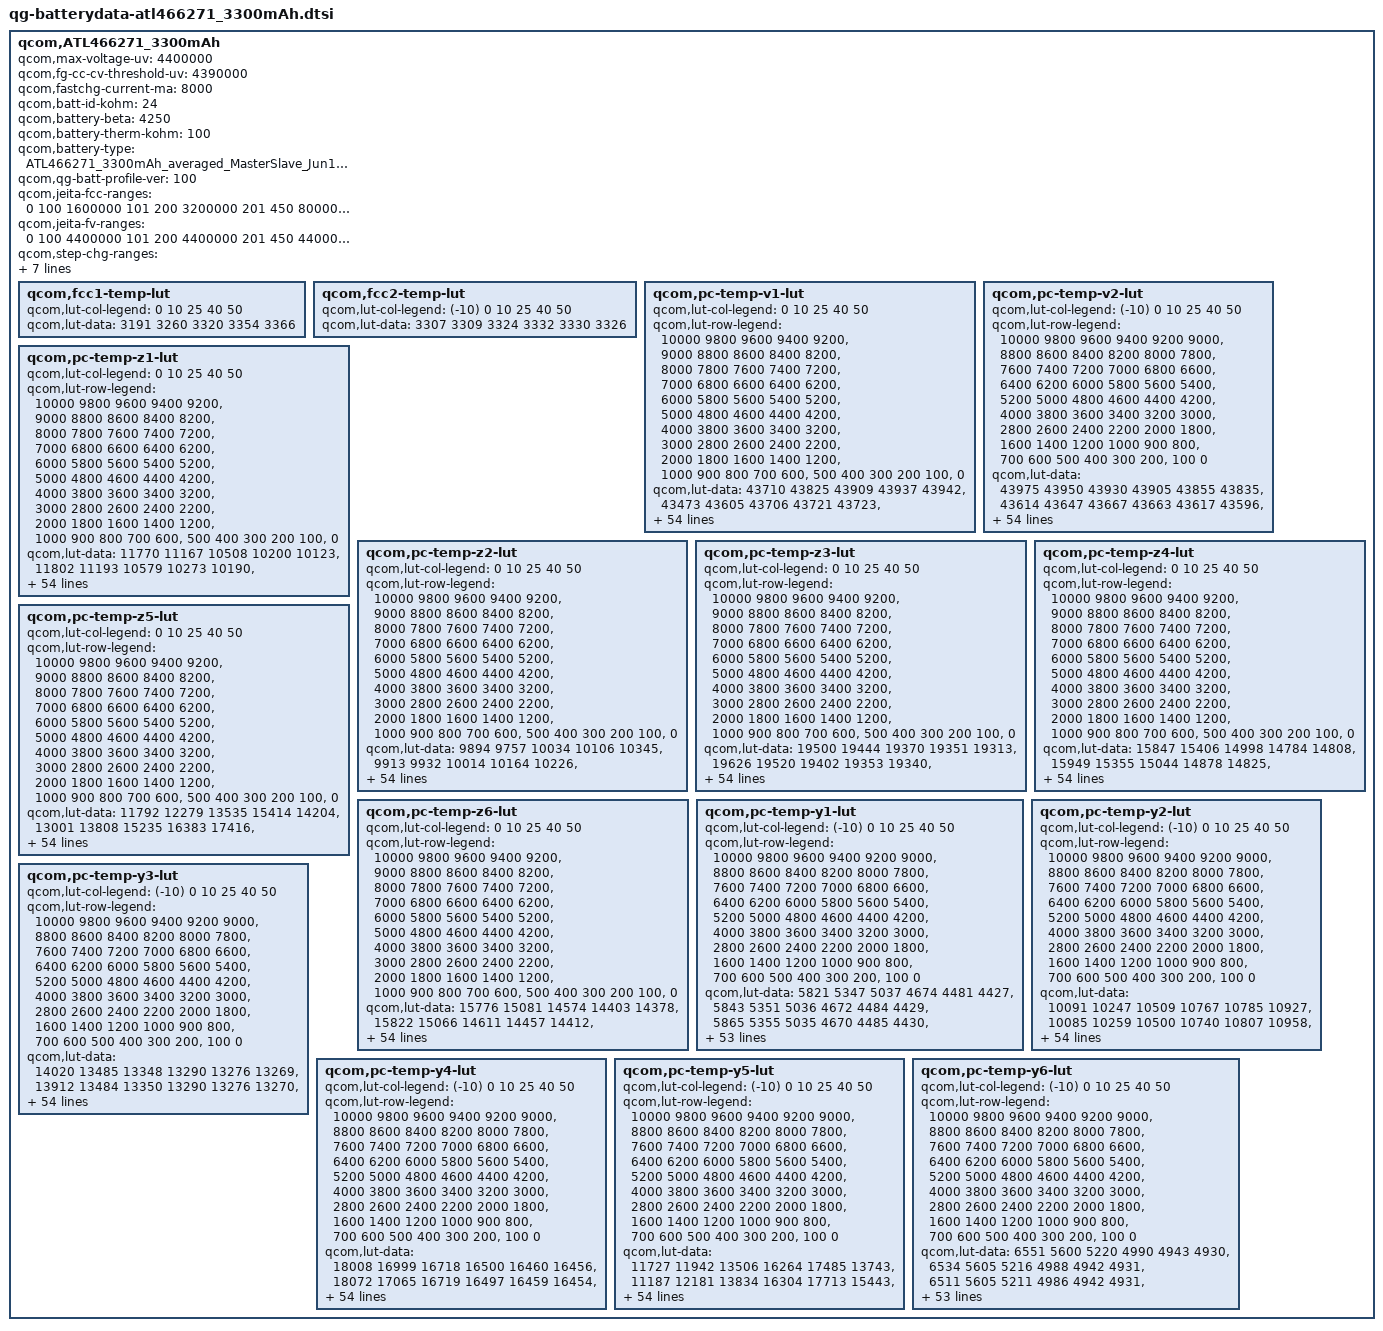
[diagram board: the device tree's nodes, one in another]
/*
 * Copyright (c) 2019, The Linux Foundation. All rights reserved.
 *
 * This program is free software; you can redistribute it and/or modify
 * it under the terms of the GNU General Public License version 2 and
 * only version 2 as published by the Free Software Foundation.
 *
 * This program is distributed in the hope that it will be useful,
 * but WITHOUT ANY WARRANTY; without even the implied warranty of
 * MERCHANTABILITY or FITNESS FOR A PARTICULAR PURPOSE.  See the
 * GNU General Public License for more details.
 */

qcom,ATL466271_3300mAh {
	/* ATL466271_3300mAh_averaged_MasterSlave_Jun12th2019 */
	qcom,max-voltage-uv = <4400000>;
	qcom,fg-cc-cv-threshold-uv = <4390000>;
	qcom,fastchg-current-ma = <8000>;
	qcom,batt-id-kohm = <24>;
	qcom,battery-beta = <4250>;
	qcom,battery-therm-kohm = <100>;
	qcom,battery-type =
		"ATL466271_3300mAh_averaged_MasterSlave_Jun12th2019";
	qcom,qg-batt-profile-ver = <100>;

	qcom,jeita-fcc-ranges = <0  100  1600000
				101 200  3200000
				201 450  8000000
				451 550  1600000>;

	qcom,jeita-fv-ranges = <0   100  4400000
				101 200  4400000
				201 450  4400000
				451 550  4050000>;

	qcom,step-chg-ranges = <3500000  4000000  8000000
				4000001  4200000  6000000
				4200001  4400000  4000000>;
	qcom,ocv-based-step-chg;

	/* COOL = 10 degc, WARM = 45 degC */
	qcom,jeita-soft-thresholds = <0x4ccc 0x20b8>;
	/* COLD = 0 degC, HOT = 55 degC*/
	qcom,jeita-hard-thresholds = <0x58cd 0x181d>;
	/* COOL hys = 13 degC, WARM hys = 42 degC */
	qcom,jeita-soft-hys-thresholds = <0x48d4 0x23c0>;
	qcom,jeita-soft-fcc-ua = <1600000 1600000>;
	qcom,jeita-soft-fv-uv = <4400000 4050000>;

	qcom,fcc1-temp-lut {
		qcom,lut-col-legend = <0 10 25 40 50>;
		qcom,lut-data = <3191 3260 3320 3354 3366>;
	};

	qcom,fcc2-temp-lut {
		qcom,lut-col-legend = <(-10) 0 10 25 40 50>;
		qcom,lut-data = <3307 3309 3324 3332 3330 3326>;
	};

	qcom,pc-temp-v1-lut {
		qcom,lut-col-legend = <0 10 25 40 50>;
		qcom,lut-row-legend = <10000 9800 9600 9400 9200>,
			<9000 8800 8600 8400 8200>,
			<8000 7800 7600 7400 7200>,
			<7000 6800 6600 6400 6200>,
			<6000 5800 5600 5400 5200>,
			<5000 4800 4600 4400 4200>,
			<4000 3800 3600 3400 3200>,
			<3000 2800 2600 2400 2200>,
			<2000 1800 1600 1400 1200>,
			<1000 900 800 700 600>,
			<500 400 300 200 100>,
			<0>;
		qcom,lut-data = <43710 43825 43909 43937 43942>,
			<43473 43605 43706 43721 43723>,
			<43237 43380 43489 43509 43510>,
			<43003 43150 43267 43294 43299>,
			<42775 42918 43038 43070 43079>,
			<42550 42687 42804 42837 42850>,
			<42328 42457 42573 42606 42620>,
			<42109 42230 42341 42375 42390>,
			<41894 42008 42113 42145 42161>,
			<41684 41789 41886 41917 41933>,
			<41476 41574 41663 41690 41705>,
			<41278 41360 41446 41467 41481>,
			<41103 41159 41232 41247 41261>,
			<40943 40987 41027 41035 41047>,
			<40756 40823 40831 40833 40840>,
			<40499 40625 40638 40639 40642>,
			<40235 40371 40434 40442 40448>,
			<40047 40136 40224 40241 40259>,
			<39905 39978 40039 40053 40076>,
			<39770 39845 39893 39894 39909>,
			<39637 39668 39742 39742 39748>,
			<39498 39402 39527 39546 39554>,
			<39319 39159 39260 39286 39299>,
			<39057 39018 39056 39062 39070>,
			<38841 38914 38916 38909 38913>,
			<38748 38814 38798 38783 38786>,
			<38688 38714 38686 38668 38667>,
			<38628 38621 38584 38566 38559>,
			<38566 38536 38491 38471 38460>,
			<38504 38459 38406 38380 38367>,
			<38445 38391 38330 38297 38282>,
			<38388 38330 38261 38223 38205>,
			<38337 38276 38199 38156 38134>,
			<38292 38228 38143 38095 38068>,
			<38251 38187 38095 38043 38009>,
			<38214 38146 38049 37992 37951>,
			<38182 38111 38004 37933 37881>,
			<38143 38071 37958 37869 37800>,
			<38074 38006 37895 37793 37711>,
			<37974 37903 37802 37697 37614>,
			<37864 37788 37692 37587 37506>,
			<37736 37663 37571 37457 37376>,
			<37592 37522 37433 37310 37228>,
			<37427 37351 37270 37152 37071>,
			<37293 37218 37135 37037 36964>,
			<37218 37148 37061 36976 36918>,
			<37197 37127 37043 36958 36899>,
			<37176 37114 37027 36945 36884>,
			<37152 37086 37005 36915 36845>,
			<37053 36954 36879 36723 36623>,
			<36674 36578 36526 36347 36242>,
			<36195 36086 36041 35859 35751>,
			<35574 35449 35427 35229 35116>,
			<34729 34574 34574 34362 34242>,
			<33401 33172 33225 32989 32851>,
			<30000 30000 30000 30000 30000>;
	};

	qcom,pc-temp-v2-lut {
		qcom,lut-col-legend = <(-10) 0 10 25 40 50>;
		qcom,lut-row-legend = <10000 9800 9600 9400 9200 9000>,
			<8800 8600 8400 8200 8000 7800>,
			<7600 7400 7200 7000 6800 6600>,
			<6400 6200 6000 5800 5600 5400>,
			<5200 5000 4800 4600 4400 4200>,
			<4000 3800 3600 3400 3200 3000>,
			<2800 2600 2400 2200 2000 1800>,
			<1600 1400 1200 1000 900 800>,
			<700 600 500 400 300 200>,
			<100 0>;
		qcom,lut-data = <43975 43950 43930 43905 43855 43835>,
			<43614 43647 43667 43663 43617 43596>,
			<43279 43361 43410 43424 43383 43362>,
			<42972 43092 43162 43188 43150 43130>,
			<42688 42841 42921 42956 42921 42903>,
			<42432 42596 42682 42724 42691 42675>,
			<42220 42350 42446 42490 42458 42443>,
			<42020 42110 42212 42257 42225 42210>,
			<41772 41881 41982 42027 41995 41980>,
			<41458 41662 41755 41799 41766 41751>,
			<41235 41448 41531 41574 41541 41526>,
			<41153 41235 41310 41352 41318 41305>,
			<41088 41026 41094 41134 41100 41087>,
			<40904 40832 40899 40930 40893 40877>,
			<40447 40653 40720 40736 40694 40672>,
			<40034 40458 40525 40537 40495 40472>,
			<39788 40221 40292 40319 40288 40277>,
			<39585 39967 40050 40106 40087 40088>,
			<39406 39734 39841 39926 39912 39913>,
			<39248 39515 39652 39767 39754 39750>,
			<39074 39305 39456 39583 39572 39566>,
			<38832 39100 39232 39336 39328 39323>,
			<38584 38908 39017 39089 39082 39080>,
			<38426 38747 38845 38906 38903 38901>,
			<38310 38609 38699 38752 38755 38754>,
			<38226 38477 38570 38621 38627 38625>,
			<38164 38335 38453 38506 38513 38511>,
			<38113 38204 38348 38403 38410 38407>,
			<38062 38112 38253 38308 38314 38311>,
			<38014 38043 38166 38221 38224 38220>,
			<37968 37988 38082 38140 38142 38137>,
			<37925 37942 37996 38064 38067 38062>,
			<37882 37901 37921 37993 37995 37989>,
			<37836 37861 37870 37925 37926 37914>,
			<37789 37823 37831 37859 37858 37837>,
			<37739 37781 37790 37789 37775 37745>,
			<37688 37735 37747 37715 37668 37625>,
			<37631 37682 37698 37637 37559 37505>,
			<37562 37619 37632 37559 37469 37410>,
			<37480 37542 37547 37477 37386 37325>,
			<37385 37449 37447 37382 37290 37228>,
			<37268 37321 37322 37269 37178 37113>,
			<37144 37177 37181 37135 37045 36979>,
			<37027 37026 37025 36987 36895 36830>,
			<36932 36918 36939 36908 36841 36784>,
			<36855 36857 36899 36885 36818 36762>,
			<36812 36827 36875 36867 36801 36749>,
			<36761 36786 36846 36843 36779 36722>,
			<36679 36721 36775 36779 36692 36597>,
			<36475 36551 36546 36552 36390 36264>,
			<36066 36173 36127 36133 35937 35797>,
			<35499 35647 35579 35596 35370 35211>,
			<34766 34968 34863 34909 34633 34453>,
			<33784 34024 33935 33996 33658 33408>,
			<32412 32711 32567 32650 31840 31311>,
			<28215 28831 27522 28579 27814 27518>;
	};

	qcom,pc-temp-z1-lut {
		qcom,lut-col-legend = <0 10 25 40 50>;
		qcom,lut-row-legend = <10000 9800 9600 9400 9200>,
			<9000 8800 8600 8400 8200>,
			<8000 7800 7600 7400 7200>,
			<7000 6800 6600 6400 6200>,
			<6000 5800 5600 5400 5200>,
			<5000 4800 4600 4400 4200>,
			<4000 3800 3600 3400 3200>,
			<3000 2800 2600 2400 2200>,
			<2000 1800 1600 1400 1200>,
			<1000 900 800 700 600>,
			<500 400 300 200 100>,
			<0>;
		qcom,lut-data = <11770 11167 10508 10200 10123>,
			<11802 11193 10579 10273 10190>,
			<11806 11200 10581 10275 10191>,
			<11805 11183 10570 10275 10191>,
			<11792 11170 10557 10270 10189>,
			<11777 11154 10545 10264 10185>,
			<11765 11131 10537 10259 10182>,
			<11755 11116 10530 10255 10180>,
			<11743 11111 10524 10251 10178>,
			<11735 11108 10520 10250 10177>,
			<11730 11108 10517 10249 10175>,
			<11726 11108 10514 10248 10174>,
			<11721 11108 10512 10248 10173>,
			<11717 11105 10511 10247 10173>,
			<11714 11099 10510 10247 10172>,
			<11704 11097 10508 10245 10172>,
			<11693 11095 10507 10245 10172>,
			<11693 11095 10506 10245 10172>,
			<11704 11097 10506 10246 10174>,
			<11714 11101 10509 10248 10175>,
			<11726 11106 10513 10252 10177>,
			<11741 11114 10517 10254 10179>,
			<11744 11122 10522 10256 10181>,
			<11737 11128 10527 10258 10183>,
			<11732 11133 10532 10260 10185>,
			<11733 11134 10537 10264 10187>,
			<11737 11132 10542 10267 10190>,
			<11740 11131 10548 10272 10194>,
			<11743 11133 10553 10276 10197>,
			<11747 11137 10558 10280 10200>,
			<11750 11142 10564 10285 10203>,
			<11754 11154 10571 10288 10206>,
			<11758 11165 10579 10292 10209>,
			<11769 11165 10584 10296 10213>,
			<11781 11161 10589 10301 10217>,
			<11789 11159 10594 10306 10221>,
			<11796 11169 10600 10312 10225>,
			<11803 11182 10606 10317 10229>,
			<11809 11185 10612 10322 10233>,
			<11816 11186 10619 10326 10236>,
			<11819 11188 10625 10330 10239>,
			<11821 11199 10630 10335 10243>,
			<11823 11208 10636 10340 10246>,
			<11826 11206 10642 10342 10248>,
			<11820 11215 10648 10344 10249>,
			<11820 11220 10655 10347 10250>,
			<11830 11225 10660 10348 10252>,
			<11816 11232 10658 10350 10253>,
			<11831 11224 10662 10354 10257>,
			<11856 11221 10671 10358 10261>,
			<11833 11233 10673 10362 10265>,
			<11848 11251 10678 10368 10270>,
			<11885 11257 10688 10374 10275>,
			<11898 11288 10702 10382 10282>,
			<11898 11288 10702 10382 10282>,
			<11898 11288 10702 10382 10282>;
	};

	qcom,pc-temp-z2-lut {
		qcom,lut-col-legend = <0 10 25 40 50>;
		qcom,lut-row-legend = <10000 9800 9600 9400 9200>,
			<9000 8800 8600 8400 8200>,
			<8000 7800 7600 7400 7200>,
			<7000 6800 6600 6400 6200>,
			<6000 5800 5600 5400 5200>,
			<5000 4800 4600 4400 4200>,
			<4000 3800 3600 3400 3200>,
			<3000 2800 2600 2400 2200>,
			<2000 1800 1600 1400 1200>,
			<1000 900 800 700 600>,
			<500 400 300 200 100>,
			<0>;
		qcom,lut-data = <9894 9757 10034 10106 10345>,
			<9913 9932 10014 10164 10226>,
			<9939 10003 10052 10124 10214>,
			<9961 9993 10069 10079 10205>,
			<9956 9975 10063 10081 10205>,
			<9932 9968 10050 10100 10208>,
			<9909 9964 10028 10116 10214>,
			<9894 9962 9988 10127 10224>,
			<9882 9965 9971 10137 10239>,
			<9879 9971 9979 10146 10256>,
			<9887 9975 9990 10155 10278>,
			<9899 9978 9996 10160 10293>,
			<9908 9983 10003 10160 10302>,
			<9915 10111 10010 10159 10307>,
			<9923 10305 10017 10164 10303>,
			<9937 10319 10021 10171 10296>,
			<9949 10152 10020 10170 10294>,
			<9950 10028 10015 10163 10294>,
			<9944 10019 10013 10158 10295>,
			<9940 10013 10022 10178 10307>,
			<9940 10015 10039 10212 10331>,
			<9943 10049 10081 10217 10334>,
			<9948 10079 10155 10205 10297>,
			<9962 10074 10180 10185 10246>,
			<9973 10059 10141 10123 10180>,
			<9974 10052 10094 10050 10113>,
			<9972 10052 10070 10041 10102>,
			<9972 10053 10053 10046 10113>,
			<9973 10046 10049 10054 10127>,
			<9975 10033 10060 10064 10141>,
			<9976 10029 10075 10077 10158>,
			<9978 10038 10091 10098 10180>,
			<9980 10052 10108 10129 10208>,
			<9983 10064 10127 10163 10243>,
			<9988 10077 10148 10206 10293>,
			<9992 10087 10168 10244 10345>,
			<9997 10095 10183 10263 10380>,
			<10003 10102 10195 10276 10409>,
			<10012 10114 10208 10287 10417>,
			<10023 10130 10226 10298 10403>,
			<10024 10137 10237 10306 10390>,
			<10014 10120 10220 10308 10389>,
			<10008 10106 10192 10307 10384>,
			<10006 10106 10186 10298 10361>,
			<10058 10124 10199 10299 10329>,
			<10061 10124 10204 10309 10360>,
			<10054 10113 10214 10301 10359>,
			<10052 10093 10207 10352 10392>,
			<10039 10104 10227 10397 10452>,
			<9972 10155 10228 10268 10254>,
			<10081 10129 10171 10193 10218>,
			<10034 10095 10128 10161 10175>,
			<9993 10043 10103 10128 10146>,
			<9836 9993 10057 10083 10063>,
			<9836 9993 10057 10083 10063>,
			<9836 9993 10057 10083 10063>;
	};

	qcom,pc-temp-z3-lut {
		qcom,lut-col-legend = <0 10 25 40 50>;
		qcom,lut-row-legend = <10000 9800 9600 9400 9200>,
			<9000 8800 8600 8400 8200>,
			<8000 7800 7600 7400 7200>,
			<7000 6800 6600 6400 6200>,
			<6000 5800 5600 5400 5200>,
			<5000 4800 4600 4400 4200>,
			<4000 3800 3600 3400 3200>,
			<3000 2800 2600 2400 2200>,
			<2000 1800 1600 1400 1200>,
			<1000 900 800 700 600>,
			<500 400 300 200 100>,
			<0>;
		qcom,lut-data = <19500 19444 19370 19351 19313>,
			<19626 19520 19402 19353 19340>,
			<19677 19560 19426 19362 19348>,
			<19706 19570 19435 19369 19353>,
			<19708 19575 19432 19369 19353>,
			<19704 19574 19427 19367 19351>,
			<19701 19566 19421 19364 19348>,
			<19699 19557 19414 19360 19345>,
			<19697 19549 19409 19355 19341>,
			<19692 19541 19406 19353 19340>,
			<19680 19535 19404 19352 19339>,
			<19665 19529 19401 19351 19338>,
			<19649 19525 19397 19351 19337>,
			<19632 19526 19395 19351 19336>,
			<19625 19529 19394 19350 19335>,
			<19632 19529 19394 19349 19331>,
			<19639 19523 19394 19348 19329>,
			<19638 19517 19394 19347 19327>,
			<19628 19510 19394 19345 19325>,
			<19621 19502 19390 19341 19323>,
			<19618 19501 19385 19335 19320>,
			<19616 19515 19389 19337 19322>,
			<19618 19527 19402 19355 19339>,
			<19632 19520 19415 19369 19354>,
			<19643 19503 19428 19376 19357>,
			<19638 19499 19437 19380 19359>,
			<19626 19519 19437 19380 19359>,
			<19619 19539 19434 19373 19356>,
			<19618 19539 19430 19368 19353>,
			<19618 19535 19425 19366 19350>,
			<19619 19530 19418 19364 19347>,
			<19621 19524 19413 19362 19343>,
			<19622 19517 19409 19358 19340>,
			<19621 19512 19405 19354 19336>,
			<19618 19508 19401 19349 19331>,
			<19615 19505 19398 19346 19328>,
			<19611 19503 19397 19346 19330>,
			<19607 19500 19396 19347 19336>,
			<19603 19497 19395 19348 19339>,
			<19597 19494 19393 19350 19339>,
			<19593 19490 19390 19351 19339>,
			<19592 19487 19386 19352 19339>,
			<19588 19483 19383 19353 19339>,
			<19579 19481 19385 19354 19341>,
			<19543 19466 19382 19350 19341>,
			<19529 19450 19368 19337 19321>,
			<19525 19448 19365 19331 19318>,
			<19523 19438 19363 19324 19312>,
			<19489 19434 19359 19320 19312>,
			<19401 19438 19363 19342 19330>,
			<19514 19442 19376 19345 19331>,
			<19508 19444 19378 19345 19332>,
			<19506 19447 19381 19346 19334>,
			<19479 19451 19379 19353 19342>,
			<19479 19451 19379 19353 19342>,
			<19479 19451 19379 19353 19342>;
	};

	qcom,pc-temp-z4-lut {
		qcom,lut-col-legend = <0 10 25 40 50>;
		qcom,lut-row-legend = <10000 9800 9600 9400 9200>,
			<9000 8800 8600 8400 8200>,
			<8000 7800 7600 7400 7200>,
			<7000 6800 6600 6400 6200>,
			<6000 5800 5600 5400 5200>,
			<5000 4800 4600 4400 4200>,
			<4000 3800 3600 3400 3200>,
			<3000 2800 2600 2400 2200>,
			<2000 1800 1600 1400 1200>,
			<1000 900 800 700 600>,
			<500 400 300 200 100>,
			<0>;
		qcom,lut-data = <15847 15406 14998 14784 14808>,
			<15949 15355 15044 14878 14825>,
			<15794 15280 14959 14838 14798>,
			<15524 15160 14880 14782 14745>,
			<15335 15024 14821 14755 14725>,
			<15199 14932 14776 14735 14717>,
			<15092 14862 14760 14724 14712>,
			<15007 14818 14752 14719 14708>,
			<14938 14795 14745 14715 14704>,
			<14892 14781 14736 14710 14700>,
			<14861 14774 14728 14704 14696>,
			<14839 14771 14722 14699 14691>,
			<14823 14768 14716 14693 14687>,
			<14809 14746 14714 14688 14682>,
			<14805 14717 14714 14683 14677>,
			<14837 14717 14714 14679 14672>,
			<14877 14763 14713 14676 14669>,
			<14877 14798 14707 14672 14666>,
			<14845 14782 14700 14669 14663>,
			<14819 14748 14691 14667 14660>,
			<14809 14748 14684 14665 14657>,
			<14802 14849 14717 14676 14662>,
			<14817 14940 14810 14736 14713>,
			<14926 14941 14844 14773 14752>,
			<15018 14932 14810 14755 14738>,
			<15011 14916 14769 14725 14711>,
			<14979 14870 14751 14712 14699>,
			<14949 14826 14739 14706 14693>,
			<14922 14811 14733 14701 14688>,
			<14898 14803 14730 14696 14684>,
			<14881 14800 14728 14693 14681>,
			<14867 14800 14728 14691 14678>,
			<14859 14800 14727 14689 14675>,
			<14855 14800 14728 14689 14674>,
			<14853 14801 14730 14689 14673>,
			<14850 14801 14732 14690 14672>,
			<14845 14800 14733 14694 14676>,
			<14843 14799 14734 14701 14687>,
			<14846 14800 14735 14703 14692>,
			<14851 14805 14736 14701 14691>,
			<14852 14807 14737 14699 14691>,
			<14843 14799 14733 14696 14691>,
			<14831 14786 14724 14692 14690>,
			<14819 14776 14719 14690 14690>,
			<14767 14740 14703 14678 14676>,
			<14740 14710 14680 14653 14645>,
			<14731 14703 14668 14647 14637>,
			<14725 14696 14656 14637 14627>,
			<14741 14692 14651 14632 14622>,
			<14832 14699 14662 14641 14641>,
			<14739 14707 14661 14645 14646>,
			<14748 14705 14661 14648 14648>,
			<14752 14704 14661 14650 14649>,
			<14789 14699 14665 14647 14645>,
			<14789 14699 14665 14647 14645>,
			<14789 14699 14665 14647 14645>;
	};

	qcom,pc-temp-z5-lut {
		qcom,lut-col-legend = <0 10 25 40 50>;
		qcom,lut-row-legend = <10000 9800 9600 9400 9200>,
			<9000 8800 8600 8400 8200>,
			<8000 7800 7600 7400 7200>,
			<7000 6800 6600 6400 6200>,
			<6000 5800 5600 5400 5200>,
			<5000 4800 4600 4400 4200>,
			<4000 3800 3600 3400 3200>,
			<3000 2800 2600 2400 2200>,
			<2000 1800 1600 1400 1200>,
			<1000 900 800 700 600>,
			<500 400 300 200 100>,
			<0>;
		qcom,lut-data = <11792 12279 13535 15414 14204>,
			<13001 13808 15235 16383 17416>,
			<13841 15100 16456 17237 19077>,
			<14514 16104 17533 18315 20517>,
			<15113 17028 18754 19244 21245>,
			<15689 18181 19650 20146 21743>,
			<16375 19593 19683 20412 21915>,
			<17353 20752 19475 20064 21544>,
			<18570 21607 19385 19726 21069>,
			<19714 22312 19837 19833 21119>,
			<20922 22624 20368 20227 21592>,
			<21654 22649 20366 20704 22135>,
			<21494 22792 20190 21409 22819>,
			<21073 24392 20127 22129 23478>,
			<21017 26764 20584 22757 23767>,
			<22555 26941 21094 23386 23725>,
			<24349 24455 21214 23801 23655>,
			<24216 22548 21439 24313 23878>,
			<22900 22853 21828 24599 24211>,
			<22166 23930 23250 24474 24553>,
			<23067 25813 24579 24129 24960>,
			<25218 31144 24161 23371 24839>,
			<27733 35337 22682 21648 23111>,
			<31628 31478 21716 20674 21705>,
			<34089 22242 21182 20941 21493>,
			<31865 19114 20879 21395 21408>,
			<26536 20884 21549 21643 21618>,
			<23985 23280 23503 21875 22646>,
			<23503 25063 24966 22255 23786>,
			<23364 26728 25863 23569 24665>,
			<23874 27767 26627 25316 25537>,
			<25339 28404 27366 26549 26565>,
			<26580 28812 28051 27647 27783>,
			<27299 28952 28637 28369 28438>,
			<27859 29013 29244 28922 28605>,
			<28127 28980 29596 29269 28749>,
			<28121 28632 29354 28928 29008>,
			<28035 28071 28613 27970 29397>,
			<28032 27480 27672 27629 29838>,
			<28024 26731 26146 27677 30769>,
			<27889 25936 24626 27779 31609>,
			<27436 24934 23369 28434 31801>,
			<26929 24388 22499 29368 31887>,
			<26421 24450 22608 28936 31937>,
			<27988 25663 22852 26365 31185>,
			<27430 25453 21972 22626 21099>,
			<26554 25602 22352 22600 22211>,
			<26806 23914 24361 22775 24450>,
			<23478 23641 24736 23227 28936>,
			<18946 23905 22228 28971 29716>,
			<23561 21707 23990 27451 26335>,
			<20333 21474 23601 25150 24619>,
			<18967 20996 23606 23367 22997>,
			<16796 21104 21653 24495 23716>,
			<16796 21104 21653 24495 23716>,
			<16796 21104 21653 24495 23716>;
	};

	qcom,pc-temp-z6-lut {
		qcom,lut-col-legend = <0 10 25 40 50>;
		qcom,lut-row-legend = <10000 9800 9600 9400 9200>,
			<9000 8800 8600 8400 8200>,
			<8000 7800 7600 7400 7200>,
			<7000 6800 6600 6400 6200>,
			<6000 5800 5600 5400 5200>,
			<5000 4800 4600 4400 4200>,
			<4000 3800 3600 3400 3200>,
			<3000 2800 2600 2400 2200>,
			<2000 1800 1600 1400 1200>,
			<1000 900 800 700 600>,
			<500 400 300 200 100>,
			<0>;
		qcom,lut-data = <15776 15081 14574 14403 14378>,
			<15822 15066 14611 14457 14412>,
			<15728 15042 14587 14444 14404>,
			<15561 14985 14560 14425 14386>,
			<15434 14901 14531 14412 14376>,
			<15332 14840 14504 14402 14371>,
			<15250 14790 14491 14394 14367>,
			<15184 14755 14482 14389 14362>,
			<15130 14736 14475 14384 14359>,
			<15088 14723 14469 14380 14356>,
			<15057 14715 14464 14377 14353>,
			<15033 14710 14459 14374 14350>,
			<15014 14704 14454 14371 14348>,
			<14997 14693 14451 14368 14345>,
			<14991 14680 14450 14366 14342>,
			<15002 14679 14449 14363 14338>,
			<15017 14691 14448 14361 14335>,
			<15016 14701 14446 14359 14333>,
			<14999 14693 14443 14357 14331>,
			<14987 14676 14438 14354 14328>,
			<14985 14676 14433 14350 14326>,
			<14985 14729 14451 14357 14329>,
			<14996 14777 14500 14394 14362>,
			<15054 14775 14519 14417 14387>,
			<15101 14767 14512 14412 14383>,
			<15097 14759 14503 14404 14374>,
			<15080 14752 14497 14398 14368>,
			<15067 14746 14492 14393 14365>,
			<15057 14742 14488 14389 14362>,
			<15050 14739 14484 14386 14358>,
			<15047 14737 14482 14384 14356>,
			<15045 14735 14480 14382 14353>,
			<15045 14734 14478 14379 14350>,
			<15046 14734 14478 14378 14347>,
			<15047 14735 14478 14376 14345>,
			<15049 14736 14479 14375 14343>,
			<15050 14738 14480 14377 14345>,
			<15052 14740 14481 14381 14354>,
			<15055 14743 14482 14384 14358>,
			<15061 14747 14484 14384 14358>,
			<15065 14749 14485 14385 14359>,
			<15066 14747 14482 14385 14359>,
			<15067 14746 14478 14385 14360>,
			<15067 14745 14478 14385 14361>,
			<15047 14732 14473 14378 14356>,
			<15035 14716 14457 14362 14333>,
			<15030 14712 14451 14356 14327>,
			<15027 14706 14445 14348 14320>,
			<15020 14704 14442 14344 14318>,
			<15023 14714 14450 14360 14336>,
			<15046 14724 14459 14366 14341>,
			<15055 14730 14462 14368 14344>,
			<15068 14739 14467 14371 14347>,
			<15088 14751 14472 14376 14351>,
			<15088 14751 14472 14376 14351>,
			<15088 14751 14472 14376 14351>;
	};

	qcom,pc-temp-y1-lut {
		qcom,lut-col-legend = <(-10) 0 10 25 40 50>;
		qcom,lut-row-legend = <10000 9800 9600 9400 9200 9000>,
			<8800 8600 8400 8200 8000 7800>,
			<7600 7400 7200 7000 6800 6600>,
			<6400 6200 6000 5800 5600 5400>,
			<5200 5000 4800 4600 4400 4200>,
			<4000 3800 3600 3400 3200 3000>,
			<2800 2600 2400 2200 2000 1800>,
			<1600 1400 1200 1000 900 800>,
			<700 600 500 400 300 200>,
			<100 0>;
		qcom,lut-data = <5821 5347 5037 4674 4481 4427>,
			<5843 5351 5036 4672 4484 4429>,
			<5865 5355 5035 4670 4485 4430>,
			<5883 5361 5033 4667 4485 4430>,
			<5897 5365 5031 4664 4484 4431>,
			<5903 5367 5030 4660 4482 4431>,
			<5900 5367 5025 4656 4477 4430>,
			<5895 5365 5019 4650 4473 4429>,
			<5896 5364 5014 4646 4472 4427>,
			<5901 5359 5010 4643 4472 4425>,
			<5903 5356 5008 4640 4472 4423>,
			<5904 5358 5011 4637 4470 4422>,
			<5908 5361 5015 4634 4468 4422>,
			<5911 5361 5013 4632 4467 4421>,
			<5920 5359 5004 4630 4465 4419>,
			<5925 5358 5000 4629 4464 4419>,
			<5922 5365 5003 4629 4464 4419>,
			<5917 5374 5007 4629 4464 4419>,
			<5917 5376 5008 4629 4464 4419>,
			<5916 5373 5005 4630 4465 4419>,
			<5914 5372 5003 4631 4465 4419>,
			<5914 5377 5004 4633 4467 4420>,
			<5916 5382 5005 4635 4469 4422>,
			<5917 5383 5005 4638 4469 4422>,
			<5917 5382 5006 4640 4469 4422>,
			<5917 5382 5008 4643 4470 4423>,
			<5915 5390 5013 4646 4472 4423>,
			<5911 5400 5019 4650 4474 4424>,
			<5907 5401 5024 4654 4476 4426>,
			<5900 5398 5029 4659 4479 4428>,
			<5896 5395 5032 4664 4481 4430>,
			<5906 5395 5032 4669 4484 4431>,
			<5922 5398 5032 4675 4487 4432>,
			<5932 5401 5035 4679 4490 4434>,
			<5943 5403 5043 4682 4493 4437>,
			<5946 5405 5047 4686 4496 4440>,
			<5933 5401 5047 4691 4499 4442>,
			<5912 5395 5048 4695 4501 4444>,
			<5901 5393 5053 4701 4504 4445>,
			<5892 5393 5061 4707 4506 4446>,
			<5887 5393 5065 4710 4509 4448>,
			<5896 5394 5064 4713 4511 4451>,
			<5900 5398 5066 4715 4513 4451>,
			<5883 5418 5079 4717 4515 4451>,
			<5915 5410 5075 4725 4518 4454>,
			<5906 5399 5089 4726 4521 4456>,
			<5899 5402 5088 4727 4519 4457>,
			<5893 5400 5081 4734 4522 4457>,
			<5894 5416 5082 4737 4521 4457>,
			<5893 5422 5089 4735 4523 4458>,
			<5951 5403 5099 4738 4525 4460>,
			<5978 5411 5100 4752 4529 4462>,
			<5943 5406 5107 4748 4534 4464>,
			<5955 5420 5108 4757 4536 4469>,
			<5955 5420 5108 4757 4536 4469>,
			<5955 5420 5108 4757 4536 4469>;
	};

	qcom,pc-temp-y2-lut {
		qcom,lut-col-legend = <(-10) 0 10 25 40 50>;
		qcom,lut-row-legend = <10000 9800 9600 9400 9200 9000>,
			<8800 8600 8400 8200 8000 7800>,
			<7600 7400 7200 7000 6800 6600>,
			<6400 6200 6000 5800 5600 5400>,
			<5200 5000 4800 4600 4400 4200>,
			<4000 3800 3600 3400 3200 3000>,
			<2800 2600 2400 2200 2000 1800>,
			<1600 1400 1200 1000 900 800>,
			<700 600 500 400 300 200>,
			<100 0>;
		qcom,lut-data = <10091 10247 10509 10767 10785 10927>,
			<10085 10259 10500 10740 10807 10958>,
			<10082 10274 10489 10711 10818 10974>,
			<10082 10288 10479 10684 10821 10978>,
			<10084 10301 10470 10661 10818 10974>,
			<10088 10309 10463 10643 10813 10967>,
			<10129 10314 10458 10630 10787 10948>,
			<10196 10318 10454 10619 10754 10920>,
			<10242 10317 10452 10606 10748 10891>,
			<10309 10310 10448 10589 10749 10854>,
			<10343 10306 10446 10578 10750 10833>,
			<10348 10349 10451 10581 10744 10834>,
			<10361 10433 10462 10588 10735 10837>,
			<10354 10516 10482 10588 10734 10833>,
			<10267 10617 10525 10585 10733 10822>,
			<10196 10671 10577 10591 10733 10816>,
			<9993 10677 10646 10622 10733 10824>,
			<9724 10679 10709 10670 10734 10837>,
			<9677 10682 10732 10741 10732 10847>,
			<9671 10689 10745 10841 10729 10857>,
			<9668 10692 10750 10877 10736 10873>,
			<9666 10695 10747 10828 10833 10914>,
			<9664 10701 10743 10775 10940 10965>,
			<9663 10698 10754 10784 10956 10999>,
			<9661 10676 10777 10824 10960 11030>,
			<9660 10640 10792 10857 10965 11054>,
			<9659 10551 10798 10880 10972 11078>,
			<9658 10416 10805 10900 10980 11102>,
			<9657 10287 10820 10916 10994 11121>,
			<9656 10134 10847 10930 11021 11137>,
			<9656 10010 10858 10948 11048 11156>,
			<9655 9913 10844 10989 11077 11185>,
			<9655 9833 10824 11022 11105 11210>,
			<9654 9791 10807 11021 11137 11220>,
			<9654 9761 10786 11011 11170 11226>,
			<9654 9737 10768 11005 11177 11228>,
			<9654 9716 10753 11011 11139 11200>,
			<9654 9699 10737 11017 11102 11170>,
			<9653 9689 10712 11012 11096 11161>,
			<9653 9681 10675 10996 11093 11144>,
			<9653 9675 10616 10980 11081 11118>,
			<9653 9671 10491 10961 11032 11066>,
			<9653 9667 10377 10936 11009 11056>,
			<9653 9664 10284 10902 11002 11096>,
			<9653 9661 10205 10867 11000 10997>,
			<9652 9659 10189 10820 10935 10941>,
			<9652 9659 10170 10842 10880 10907>,
			<9652 9658 10266 10786 10907 10898>,
			<9652 9657 10342 10819 10926 10908>,
			<9652 9656 10250 10823 10875 10851>,
			<9652 9655 10037 10750 10829 10802>,
			<9652 9654 9972 10651 10750 10766>,
			<9651 9653 9891 10735 10690 10675>,
			<9650 9653 10171 10679 10569 10544>,
			<9650 9653 10171 10679 10569 10544>,
			<9650 9653 10171 10679 10569 10544>;
	};

	qcom,pc-temp-y3-lut {
		qcom,lut-col-legend = <(-10) 0 10 25 40 50>;
		qcom,lut-row-legend = <10000 9800 9600 9400 9200 9000>,
			<8800 8600 8400 8200 8000 7800>,
			<7600 7400 7200 7000 6800 6600>,
			<6400 6200 6000 5800 5600 5400>,
			<5200 5000 4800 4600 4400 4200>,
			<4000 3800 3600 3400 3200 3000>,
			<2800 2600 2400 2200 2000 1800>,
			<1600 1400 1200 1000 900 800>,
			<700 600 500 400 300 200>,
			<100 0>;
		qcom,lut-data = <14020 13485 13348 13290 13276 13269>,
			<13912 13484 13350 13290 13276 13270>,
			<13847 13482 13351 13290 13277 13271>,
			<13814 13481 13352 13290 13277 13272>,
			<13802 13479 13353 13290 13278 13274>,
			<13800 13477 13353 13290 13278 13274>,
			<13846 13474 13353 13290 13278 13275>,
			<13915 13471 13353 13289 13279 13275>,
			<13881 13472 13353 13290 13279 13275>,
			<13646 13477 13352 13291 13279 13275>,
			<13499 13480 13351 13292 13280 13275>,
			<13535 13470 13351 13294 13280 13276>,
			<13592 13454 13351 13296 13280 13277>,
			<13605 13449 13352 13297 13281 13277>,
			<13589 13442 13356 13297 13282 13277>,
			<13574 13436 13358 13298 13282 13277>,
			<13544 13434 13352 13298 13282 13277>,
			<13507 13429 13343 13300 13283 13277>,
			<13503 13421 13341 13301 13284 13278>,
			<13510 13403 13340 13302 13285 13280>,
			<13517 13385 13338 13303 13286 13281>,
			<13521 13372 13331 13298 13282 13278>,
			<13523 13361 13323 13291 13278 13275>,
			<13523 13352 13319 13288 13277 13274>,
			<13533 13345 13316 13286 13277 13273>,
			<13553 13338 13314 13285 13276 13272>,
			<13593 13320 13311 13285 13277 13273>,
			<13646 13299 13309 13285 13277 13273>,
			<13696 13288 13308 13285 13276 13273>,
			<13750 13271 13307 13286 13276 13273>,
			<13806 13266 13305 13286 13275 13273>,
			<13866 13268 13303 13285 13275 13273>,
			<13929 13271 13301 13285 13275 13272>,
			<13994 13274 13301 13285 13275 13272>,
			<14060 13278 13303 13284 13276 13272>,
			<14134 13284 13305 13284 13277 13272>,
			<14220 13295 13307 13283 13276 13273>,
			<14312 13311 13309 13282 13275 13273>,
			<14405 13332 13311 13282 13275 13273>,
			<14501 13362 13312 13282 13276 13274>,
			<14596 13393 13313 13282 13276 13274>,
			<14687 13416 13313 13282 13277 13274>,
			<14781 13443 13314 13283 13277 13274>,
			<14884 13488 13317 13284 13276 13273>,
			<14998 13565 13322 13285 13276 13274>,
			<14988 13596 13326 13288 13278 13276>,
			<15059 13649 13330 13289 13279 13277>,
			<15152 13712 13339 13294 13283 13279>,
			<15247 13784 13351 13296 13282 13277>,
			<15340 13847 13352 13295 13280 13276>,
			<15443 13922 13355 13295 13281 13277>,
			<15627 14060 13367 13298 13284 13279>,
			<15865 14258 13384 13304 13286 13283>,
			<16661 14530 13427 13312 13291 13287>,
			<16661 14530 13427 13312 13291 13287>,
			<16661 14530 13427 13312 13291 13287>;
	};

	qcom,pc-temp-y4-lut {
		qcom,lut-col-legend = <(-10) 0 10 25 40 50>;
		qcom,lut-row-legend = <10000 9800 9600 9400 9200 9000>,
			<8800 8600 8400 8200 8000 7800>,
			<7600 7400 7200 7000 6800 6600>,
			<6400 6200 6000 5800 5600 5400>,
			<5200 5000 4800 4600 4400 4200>,
			<4000 3800 3600 3400 3200 3000>,
			<2800 2600 2400 2200 2000 1800>,
			<1600 1400 1200 1000 900 800>,
			<700 600 500 400 300 200>,
			<100 0>;
		qcom,lut-data = <18008 16999 16718 16500 16460 16456>,
			<18072 17065 16719 16497 16459 16454>,
			<18111 17109 16717 16493 16457 16452>,
			<18131 17135 16714 16489 16455 16451>,
			<18138 17148 16709 16486 16453 16449>,
			<18139 17152 16703 16485 16453 16448>,
			<18029 17137 16693 16486 16452 16448>,
			<17863 17112 16683 16486 16452 16447>,
			<17896 17097 16681 16488 16452 16448>,
			<18235 17083 16680 16490 16454 16449>,
			<18508 17077 16680 16492 16455 16450>,
			<18619 17111 16683 16496 16457 16451>,
			<18700 17180 16689 16501 16461 16452>,
			<18607 17260 16712 16509 16466 16453>,
			<18107 17384 16786 16522 16473 16457>,
			<17766 17446 16846 16538 16481 16462>,
			<17718 17379 16883 16554 16487 16468>,
			<17687 17259 16908 16574 16496 16475>,
			<17629 17174 16905 16613 16516 16490>,
			<17534 17108 16880 16675 16554 16516>,
			<17407 17042 16841 16697 16568 16526>,
			<17159 16963 16746 16628 16535 16505>,
			<16891 16889 16644 16542 16492 16476>,
			<16806 16845 16607 16507 16473 16463>,
			<16770 16818 16587 16484 16461 16454>,
			<16755 16786 16580 16478 16457 16452>,
			<16753 16727 16578 16479 16457 16452>,
			<16753 16673 16578 16480 16457 16452>,
			<16756 16669 16579 16483 16459 16453>,
			<16763 16685 16581 16490 16462 16455>,
			<16771 16697 16581 16497 16467 16458>,
			<16783 16705 16558 16506 16473 16464>,
			<16797 16717 16535 16512 16481 16470>,
			<16813 16732 16538 16515 16488 16475>,
			<16831 16753 16552 16517 16495 16479>,
			<16846 16769 16568 16515 16495 16479>,
			<16858 16781 16587 16493 16474 16465>,
			<16869 16791 16601 16473 16454 16451>,
			<16877 16794 16600 16470 16450 16451>,
			<16883 16792 16599 16468 16449 16452>,
			<16885 16788 16599 16469 16448 16452>,
			<16876 16770 16608 16474 16449 16451>,
			<16865 16757 16618 16479 16448 16448>,
			<16860 16757 16628 16481 16442 16435>,
			<16879 16761 16645 16484 16444 16435>,
			<16891 16789 16652 16498 16455 16453>,
			<16943 16827 16682 16511 16475 16497>,
			<17014 16881 16733 16537 16536 16562>,
			<17081 16976 16802 16590 16557 16530>,
			<17089 17020 16800 16563 16478 16467>,
			<17047 16991 16801 16554 16477 16469>,
			<17042 17006 16834 16584 16500 16488>,
			<17105 17082 16903 16649 16553 16544>,
			<17555 17233 17100 16828 16767 16718>,
			<17555 17233 17100 16828 16767 16718>,
			<17555 17233 17100 16828 16767 16718>;
	};

	qcom,pc-temp-y5-lut {
		qcom,lut-col-legend = <(-10) 0 10 25 40 50>;
		qcom,lut-row-legend = <10000 9800 9600 9400 9200 9000>,
			<8800 8600 8400 8200 8000 7800>,
			<7600 7400 7200 7000 6800 6600>,
			<6400 6200 6000 5800 5600 5400>,
			<5200 5000 4800 4600 4400 4200>,
			<4000 3800 3600 3400 3200 3000>,
			<2800 2600 2400 2200 2000 1800>,
			<1600 1400 1200 1000 900 800>,
			<700 600 500 400 300 200>,
			<100 0>;
		qcom,lut-data = <11727 11942 13506 16264 17485 13743>,
			<11187 12181 13834 16304 17713 15443>,
			<10948 12440 14154 16154 17943 16969>,
			<10946 12689 14439 15889 18142 18238>,
			<11119 12897 14661 15580 18277 19164>,
			<11403 13035 14792 15300 18315 19661>,
			<12465 13100 14855 14911 18249 19739>,
			<13822 13150 14864 14518 18113 19553>,
			<13670 13301 14746 14395 17867 19106>,
			<11695 13714 14420 14341 17361 18217>,
			<10462 13958 14096 14326 16853 17639>,
			<11501 13114 13863 14506 16406 17596>,
			<13219 11865 13624 14722 15945 17611>,
			<13884 11823 13278 14498 15435 17295>,
			<13848 12774 12797 13693 14834 16535>,
			<13691 13748 12589 13309 14470 15845>,
			<13167 14554 12751 13334 14271 15143>,
			<12586 15195 13107 13390 14142 14574>,
			<13020 15258 13900 13564 14152 14504>,
			<14413 15027 15523 14068 14254 14631>,
			<15535 14881 16342 14723 14446 14876>,
			<15575 14923 16444 15913 15152 15787>,
			<15061 15014 16478 16911 16165 16899>,
			<14339 15197 16434 16931 17201 17475>,
			<12334 15627 16343 16746 18331 17902>,
			<11314 15978 16268 16667 18791 18109>,
			<11399 15505 16100 16581 18776 18180>,
			<11512 14520 15934 16533 18615 18169>,
			<11525 13737 16028 16730 18175 18053>,
			<11550 12045 16380 17082 17340 17858>,
			<11588 11352 16565 17187 16713 17565>,
			<11718 11445 16382 17060 16198 16814>,
			<11865 11550 16160 16944 15883 16183>,
			<11908 11637 16198 17254 16375 16323>,
			<11980 11737 16327 17954 17689 16949>,
			<12075 11818 16423 18152 18505 17767>,
			<12422 11915 16495 17982 18987 19240>,
			<12794 12071 16540 17734 19303 20755>,
			<12843 12334 16444 17425 19669 21829>,
			<12812 12824 16116 17020 20264 22723>,
			<12740 13086 15663 16654 20463 22879>,
			<12356 12741 14862 16171 20541 22449>,
			<11882 12264 14369 16034 20626 22711>,
			<11570 11949 14152 16151 21020 24835>,
			<11487 11951 14006 15816 18734 20674>,
			<11662 11903 13943 16003 17805 20181>,
			<11655 12101 13682 15426 17094 17583>,
			<11840 12432 13801 16015 16324 15006>,
			<12476 12948 14155 15430 14898 14594>,
			<12752 13151 14323 16256 17791 17272>,
			<12081 13073 14285 16869 17629 17625>,
			<11734 12858 14199 16707 19166 17889>,
			<11770 12567 13945 17145 18317 18429>,
			<11976 12244 15223 16959 17784 17367>,
			<11976 12244 15223 16959 17784 17367>,
			<11976 12244 15223 16959 17784 17367>;
	};

	qcom,pc-temp-y6-lut {
		qcom,lut-col-legend = <(-10) 0 10 25 40 50>;
		qcom,lut-row-legend = <10000 9800 9600 9400 9200 9000>,
			<8800 8600 8400 8200 8000 7800>,
			<7600 7400 7200 7000 6800 6600>,
			<6400 6200 6000 5800 5600 5400>,
			<5200 5000 4800 4600 4400 4200>,
			<4000 3800 3600 3400 3200 3000>,
			<2800 2600 2400 2200 2000 1800>,
			<1600 1400 1200 1000 900 800>,
			<700 600 500 400 300 200>,
			<100 0>;
		qcom,lut-data = <6551 5600 5220 4990 4943 4930>,
			<6534 5605 5216 4988 4942 4931>,
			<6511 5605 5211 4986 4942 4931>,
			<6488 5601 5205 4984 4942 4931>,
			<6470 5594 5199 4983 4942 4932>,
			<6461 5584 5193 4982 4942 4932>,
			<6460 5570 5186 4981 4942 4932>,
			<6461 5554 5179 4980 4942 4932>,
			<6450 5545 5174 4981 4942 4932>,
			<6403 5538 5169 4981 4942 4933>,
			<6375 5535 5166 4982 4943 4933>,
			<6433 5536 5165 4984 4943 4933>,
			<6517 5539 5164 4987 4945 4934>,
			<6504 5548 5169 4989 4946 4935>,
			<6362 5577 5191 4993 4949 4936>,
			<6258 5593 5206 4998 4951 4938>,
			<6231 5576 5210 5003 4954 4939>,
			<6212 5543 5212 5009 4956 4942>,
			<6209 5514 5211 5021 4962 4946>,
			<6205 5486 5203 5040 4974 4955>,
			<6199 5459 5190 5046 4978 4958>,
			<6156 5431 5159 5023 4966 4950>,
			<6101 5407 5125 4994 4951 4939>,
			<6096 5397 5113 4982 4945 4934>,
			<6119 5393 5107 4974 4941 4931>,
			<6146 5387 5105 4972 4940 4930>,
			<6186 5373 5105 4973 4940 4930>,
			<6237 5359 5106 4974 4940 4931>,
			<6285 5359 5108 4975 4940 4931>,
			<6335 5374 5112 4978 4941 4932>,
			<6386 5394 5113 4981 4942 4933>,
			<6438 5418 5109 4984 4944 4934>,
			<6491 5448 5106 4986 4946 4936>,
			<6546 5478 5109 4988 4949 4938>,
			<6603 5512 5120 4989 4952 4939>,
			<6665 5547 5133 4989 4952 4939>,
			<6732 5583 5145 4983 4946 4936>,
			<6803 5621 5158 4978 4940 4932>,
			<6876 5662 5167 4978 4940 4932>,
			<6950 5708 5176 4978 4940 4933>,
			<7022 5754 5186 4979 4940 4933>,
			<7089 5799 5201 4982 4942 4934>,
			<7157 5850 5219 4985 4942 4933>,
			<7235 5915 5240 4987 4939 4929>,
			<7330 6003 5272 4991 4941 4930>,
			<7326 6045 5279 4998 4946 4937>,
			<7395 6104 5304 5003 4952 4950>,
			<7483 6173 5341 5014 4973 4970>,
			<7577 6261 5385 5032 4978 4960>,
			<7656 6331 5397 5024 4954 4941>,
			<7727 6392 5417 5023 4955 4943>,
			<7873 6517 5468 5035 4965 4950>,
			<8078 6702 5539 5060 4982 4970>,
			<8853 6954 5681 5120 5047 5023>,
			<8853 6954 5681 5120 5047 5023>,
			<8853 6954 5681 5120 5047 5023>;
	};

};
